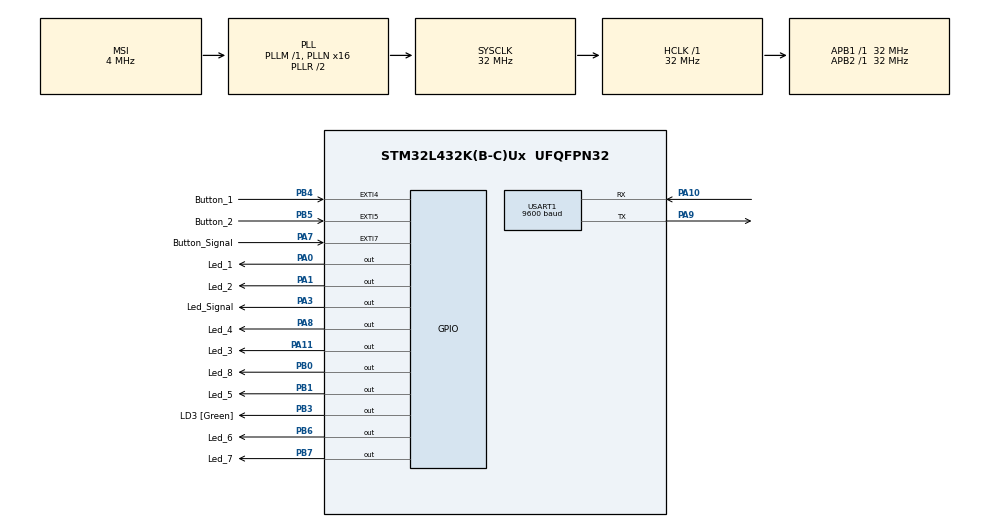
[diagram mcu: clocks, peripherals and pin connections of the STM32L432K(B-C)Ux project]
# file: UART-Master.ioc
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Mcu.Family=STM32L4
Mcu.Name=STM32L432K(B-C)Ux
Mcu.Package=UFQFPN32
NVIC.EXTI4_IRQn=true\:0\:0\:false\:false\:true\:true\:true\:true
NVIC.EXTI9_5_IRQn=true\:0\:0\:false\:false\:true\:true\:true\:true
NVIC.PriorityGroup=NVIC_PRIORITYGROUP_4
NVIC.TIM2_IRQn=true\:0\:0\:false\:false\:true\:true\:true\:true
NVIC.USART1_IRQn=true\:0\:0\:false\:false\:true\:true\:true\:true
PA0.GPIO_Label=Led_1
PA0.Signal=GPIO_Output
PA1.GPIO_Label=Led_2
PA1.Signal=GPIO_Output
PA10.Mode=Asynchronous
PA10.Signal=USART1_RX
PA11.GPIO_Label=Led_3
PA11.Signal=GPIO_Output
PA13\ (JTMS-SWDIO).GPIO_Label=SWDIO
PA13\ (JTMS-SWDIO).Mode=Serial_Wire
PA13\ (JTMS-SWDIO).Signal=SYS_JTMS-SWDIO
PA14\ (JTCK-SWCLK).GPIO_Label=SWCLK
PA14\ (JTCK-SWCLK).Mode=Serial_Wire
PA14\ (JTCK-SWCLK).Signal=SYS_JTCK-SWCLK
PA3.GPIO_Label=Led_Signal
PA3.Signal=GPIO_Output
PA7.GPIO_Label=Button_Signal
PA7.GPIO_PuPd=GPIO_PULLDOWN
PA7.Signal=GPXTI7
PA8.GPIO_Label=Led_4
PA8.Signal=GPIO_Output
PA9.Mode=Asynchronous
PA9.Signal=USART1_TX
PB0.GPIO_Label=Led_8
PB0.Signal=GPIO_Output
PB1.GPIO_Label=Led_5
PB1.Signal=GPIO_Output
PB3\ (JTDO-TRACESWO).GPIO_Label=LD3 [Green]
PB3\ (JTDO-TRACESWO).Signal=GPIO_Output
PB4\ (NJTRST).GPIO_Label=Button_1
PB4\ (NJTRST).GPIO_PuPd=GPIO_PULLDOWN
PB4\ (NJTRST).Signal=GPXTI4
PB5.GPIO_Label=Button_2
PB5.GPIO_PuPd=GPIO_PULLDOWN
PB5.Signal=GPXTI5
PB6.GPIO_Label=Led_6
PB6.Signal=GPIO_Output
PB7.GPIO_Label=Led_7
PB7.Signal=GPIO_Output
PC14-OSC32_IN\ (PC14).Mode=LSE-External-Oscillator
PC14-OSC32_IN\ (PC14).Signal=RCC_OSC32_IN
PC15-OSC32_OUT\ (PC15).Mode=LSE-External-Oscillator
PC15-OSC32_OUT\ (PC15).Signal=RCC_OSC32_OUT
ProjectManager.HeapSize=0x200
ProjectManager.StackSize=0x400
ProjectManager.TargetToolchain=CMake
RCC.AHBFreq_Value=32000000
RCC.APB1Freq_Value=32000000
RCC.APB1TimFreq_Value=32000000
RCC.APB2Freq_Value=32000000
RCC.APB2TimFreq_Value=32000000
RCC.CortexFreq_Value=32000000
RCC.HCLKFreq_Value=32000000
RCC.HSE_VALUE=8000000
RCC.HSI16_VALUE=16000000
RCC.HSI48_VALUE=48000000
RCC.HSI_VALUE=16000000
RCC.MSI_VALUE=4000000
RCC.PLLMUL=RCC_PLLMUL_4
RCC.PLLN=16
RCC.SYSCLKFreq_VALUE=32000000
RCC.SYSCLKSource=RCC_SYSCLKSOURCE_PLLCLK
RCC.VCOOutputFreq_Value=64000000
TIM2.Period=19999
TIM2.Prescaler=7999
USART1.BaudRate=9600
USART1.VirtualMode-Asynchronous=VM_ASYNC
VP_TIM2_VS_ClockSourceINT.Mode=Internal
board=NUCLEO-L432KC

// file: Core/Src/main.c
// Copyright 2026 TOK3T
/* USER CODE BEGIN Header */
/*
 ******************************************************************************
 * @file           : main.c
 * @brief          : Main program body
 ******************************************************************************
 * @attention
 *
 * Copyright (c) 2026 STMicroelectronics.
 * All rights reserved.
 *
 * This software is licensed under terms that can be found in the LICENSE file
 * in the root directory of this software component.
 * If no LICENSE file comes with this software, it is provided AS-IS.
 *
 ******************************************************************************
 */
/* USER CODE END Header */
#include "main.h"

/* USER CODE BEGIN Includes */
#include <stdio.h>
#include <string.h>
#include "leds.h"
#include "uart.h"  //NOLINT

/* USER CODE END Includes */

TIM_HandleTypeDef htim2;

UART_HandleTypeDef huart1;

/* USER CODE BEGIN PV */
// Application state moved to app.c
/* USER CODE END PV */

void SystemClock_Config(void);
static void MX_GPIO_Init(void);
static void MX_USART1_UART_Init(void);
static void MX_TIM2_Init(void);

/* USER CODE BEGIN 0 */
// Update_LEDs implemented in app.c
/* USER CODE END 0 */

int main(void) {
    /* USER CODE BEGIN 1 */
    // initialize modules
    Led_Init();
    /* USER CODE END 1 */

    /* MCU Configuration---------------------------------------------------*/

    /* Reset of all, Initializes the Flash interface and the Systick. */
    HAL_Init();

    /* Configure the system clock */
    SystemClock_Config();

    /* Initialize all configured peripherals */
    MX_GPIO_Init();
    MX_USART1_UART_Init();
    MX_TIM2_Init();
    /* USER CODE BEGIN 2 */
    // start peripherals and hand them to modules
    HAL_TIM_Base_Start_IT(&htim2);

    UART_Start(&htim2, &huart1);
    UART_SetConnectionOk(); /* arm receiver and set connected state */
    /* USER CODE END 2 */

    /* Infinite loop */
    while (1) {

    }
}

void SystemClock_Config(void) {
    RCC_OscInitTypeDef RCC_OscInitStruct = {0};
    RCC_ClkInitTypeDef RCC_ClkInitStruct = {0};

    /** Configure the main internal regulator output voltage
     */
    if (HAL_PWREx_ControlVoltageScaling(PWR_REGULATOR_VOLTAGE_SCALE1) !=
        HAL_OK) {  // NOLINT
        Error_Handler();
    }

    /** Configure LSE Drive Capability
     */
    HAL_PWR_EnableBkUpAccess();
    __HAL_RCC_LSEDRIVE_CONFIG(RCC_LSEDRIVE_LOW);

    /** Initializes the RCC Oscillators according to the specified parameters
     * in the RCC_OscInitTypeDef structure.
     */
    RCC_OscInitStruct.OscillatorType =
        RCC_OSCILLATORTYPE_LSE | RCC_OSCILLATORTYPE_MSI;  // NOLINT
    RCC_OscInitStruct.LSEState = RCC_LSE_ON;
    RCC_OscInitStruct.MSIState = RCC_MSI_ON;
    RCC_OscInitStruct.MSICalibrationValue = 0;
    RCC_OscInitStruct.MSIClockRange = RCC_MSIRANGE_6;
    RCC_OscInitStruct.PLL.PLLState = RCC_PLL_ON;
    RCC_OscInitStruct.PLL.PLLSource = RCC_PLLSOURCE_MSI;
    RCC_OscInitStruct.PLL.PLLM = 1;
    RCC_OscInitStruct.PLL.PLLN = 16;
    RCC_OscInitStruct.PLL.PLLP = RCC_PLLP_DIV7;
    RCC_OscInitStruct.PLL.PLLQ = RCC_PLLQ_DIV2;
    RCC_OscInitStruct.PLL.PLLR = RCC_PLLR_DIV2;
    if (HAL_RCC_OscConfig(&RCC_OscInitStruct) != HAL_OK) {
        Error_Handler();
    }

    /** Initializes the CPU, AHB and APB buses clocks
     */
    RCC_ClkInitStruct.ClockType = RCC_CLOCKTYPE_HCLK | RCC_CLOCKTYPE_SYSCLK |
                                  RCC_CLOCKTYPE_PCLK1 |
                                  RCC_CLOCKTYPE_PCLK2;  // NOLINT
    RCC_ClkInitStruct.SYSCLKSource = RCC_SYSCLKSOURCE_PLLCLK;
    RCC_ClkInitStruct.AHBCLKDivider = RCC_SYSCLK_DIV1;
    RCC_ClkInitStruct.APB1CLKDivider = RCC_HCLK_DIV1;
    RCC_ClkInitStruct.APB2CLKDivider = RCC_HCLK_DIV1;

    if (HAL_RCC_ClockConfig(&RCC_ClkInitStruct, FLASH_LATENCY_1) != HAL_OK) {
        Error_Handler();
    }

    /** Enable MSI Auto calibration
     */
    HAL_RCCEx_EnableMSIPLLMode();
}

static void MX_TIM2_Init(void) {

    TIM_ClockConfigTypeDef sClockSourceConfig = {0};
    TIM_MasterConfigTypeDef sMasterConfig = {0};

    htim2.Instance = TIM2;
    htim2.Init.Prescaler = 7999;
    htim2.Init.CounterMode = TIM_COUNTERMODE_UP;
    htim2.Init.Period = 19999;
    htim2.Init.ClockDivision = TIM_CLOCKDIVISION_DIV1;
    htim2.Init.AutoReloadPreload = TIM_AUTORELOAD_PRELOAD_DISABLE;
    if (HAL_TIM_Base_Init(&htim2) != HAL_OK) {
        Error_Handler();
    }
    sClockSourceConfig.ClockSource = TIM_CLOCKSOURCE_INTERNAL;
    if (HAL_TIM_ConfigClockSource(&htim2, &sClockSourceConfig) !=
        HAL_OK) {  // NOLINT
        Error_Handler();
    }
    sMasterConfig.MasterOutputTrigger = TIM_TRGO_RESET;
    sMasterConfig.MasterSlaveMode = TIM_MASTERSLAVEMODE_DISABLE;
    if (HAL_TIMEx_MasterConfigSynchronization(&htim2, &sMasterConfig) !=
        HAL_OK) {  // NOLINT
        Error_Handler();
    }
}

static void MX_USART1_UART_Init(void) {

    huart1.Instance = USART1;
    huart1.Init.BaudRate = 9600;
    huart1.Init.WordLength = UART_WORDLENGTH_8B;
    huart1.Init.StopBits = UART_STOPBITS_1;
    huart1.Init.Parity = UART_PARITY_NONE;
    huart1.Init.Mode = UART_MODE_TX_RX;
    huart1.Init.HwFlowCtl = UART_HWCONTROL_NONE;
    huart1.Init.OverSampling = UART_OVERSAMPLING_16;
    huart1.Init.OneBitSampling = UART_ONE_BIT_SAMPLE_DISABLE;
    huart1.AdvancedInit.AdvFeatureInit = UART_ADVFEATURE_NO_INIT;
    if (HAL_UART_Init(&huart1) != HAL_OK) {
        Error_Handler();
    }
}

static void MX_GPIO_Init(void) {
    GPIO_InitTypeDef GPIO_InitStruct = {0};

    /* GPIO Ports Clock Enable */
    __HAL_RCC_GPIOC_CLK_ENABLE();
    __HAL_RCC_GPIOA_CLK_ENABLE();
    __HAL_RCC_GPIOB_CLK_ENABLE();

    /*Configure GPIO pin Output Level */
    HAL_GPIO_WritePin(GPIOA,
                      Led_1_Pin | Led_2_Pin | Led_Signal_Pin | Led_4_Pin |
                          Led_3_Pin,  // NOLINT
                      GPIO_PIN_RESET);

    /*Configure GPIO pin Output Level */
    HAL_GPIO_WritePin(
        GPIOB,
        Led_8_Pin | Led_5_Pin | LD3_Pin | Led_6_Pin | Led_7_Pin,  // NOLINT
        GPIO_PIN_RESET);

    /*Configure GPIO pins : Led_1_Pin Led_2_Pin Led_Signal_Pin Led_4_Pin
                           Led_3_Pin */
    GPIO_InitStruct.Pin = Led_1_Pin | Led_2_Pin | Led_Signal_Pin;
    GPIO_InitStruct.Pin = Led_4_Pin | Led_3_Pin;
    GPIO_InitStruct.Mode = GPIO_MODE_OUTPUT_PP;
    GPIO_InitStruct.Pull = GPIO_NOPULL;
    GPIO_InitStruct.Speed = GPIO_SPEED_FREQ_LOW;
    HAL_GPIO_Init(GPIOA, &GPIO_InitStruct);

    /*Configure GPIO pin : Button_Signal_Pin */
    GPIO_InitStruct.Pin = Button_Signal_Pin;
    GPIO_InitStruct.Mode = GPIO_MODE_IT_RISING;
    GPIO_InitStruct.Pull = GPIO_PULLDOWN;
    HAL_GPIO_Init(Button_Signal_GPIO_Port, &GPIO_InitStruct);

    /*Configure GPIO pins : Led_8_Pin Led_5_Pin LD3_Pin Led_6_Pin
                           Led_7_Pin */
    GPIO_InitStruct.Pin =
        Led_8_Pin | Led_5_Pin | LD3_Pin | Led_6_Pin | Led_7_Pin;  // NOLINT
    GPIO_InitStruct.Mode = GPIO_MODE_OUTPUT_PP;
    GPIO_InitStruct.Pull = GPIO_NOPULL;
    GPIO_InitStruct.Speed = GPIO_SPEED_FREQ_LOW;
    HAL_GPIO_Init(GPIOB, &GPIO_InitStruct);

    /*Configure GPIO pins : Button_1_Pin Button_2_Pin */
    GPIO_InitStruct.Pin = Button_1_Pin | Button_2_Pin;
    GPIO_InitStruct.Mode = GPIO_MODE_IT_RISING;
    GPIO_InitStruct.Pull = GPIO_PULLDOWN;
    HAL_GPIO_Init(GPIOB, &GPIO_InitStruct);

    /* EXTI interrupt init*/
    HAL_NVIC_SetPriority(EXTI4_IRQn, 0, 0);
    HAL_NVIC_EnableIRQ(EXTI4_IRQn);

    HAL_NVIC_SetPriority(EXTI9_5_IRQn, 0, 0);
    HAL_NVIC_EnableIRQ(EXTI9_5_IRQn);

}

/* USER CODE BEGIN 4 */
// Callbacks moved to app.c
/* USER CODE END 4 */

void Error_Handler(void) {
    __disable_irq();
    while (1) {
    }
    /* USER CODE END Error_Handler_Debug */
}
#ifdef USE_FULL_ASSERT
/**
 * @brief  Reports the name of the source file and the source line number
 *         where the assert_param error has occurred.
 * @param  file: pointer to the source file name
 * @param  line: assert_param error line source number
 * @retval None
 */
void assert_failed(uint8_t* file, uint32_t line) {
    /* USER CODE BEGIN 6 */
    /* User can add his own implementation to report the file name and line
     number, ex: printf("Wrong parameters value: file %s on line %d\r\n", file,
     line) */
    /* USER CODE END 6 */
}
#endif /* USE_FULL_ASSERT */
